# ATSAMG53 register map
Vendor: Microchip Technology; Series: SAMG53; File version: 0
CPU: CM4 r0p1, little endian, MPU, FPU, 4 interrupt priority bits
Registers are 32-bit, read-write, reset 0x0 unless marked. A register's access mark holds for its fields unless they carry their own. Offsets are from the block's base; [hi:lo] are bit positions; {n}, {i} and the like mark numbered series; 'fields as' and 'values as' point back to an identical list.

## USART — Universal Synchronous Asynchronous Receiver Transmitter
Base 0x40024000; register names take the prefix USART_
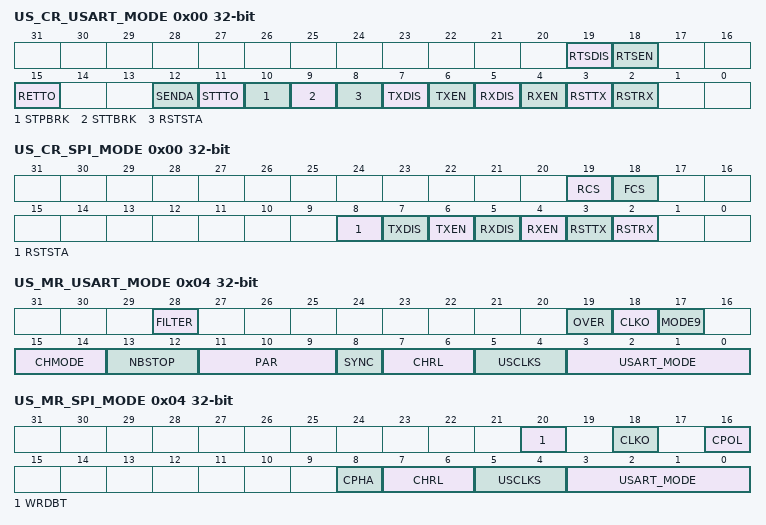
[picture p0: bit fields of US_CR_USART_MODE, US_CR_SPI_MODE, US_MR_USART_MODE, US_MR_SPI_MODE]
0x00 US_CR_USART_MODE wo — Control Register
  [19] RTSDIS — Request to Send Disable
  [18] RTSEN — Request to Send Enable
  [15] RETTO — Start Timeout Immediately
  [12] SENDA — Send Address
  [11] STTTO — Clear TIMEOUT Flag and Start Timeout After Next Character Received
  [10] STPBRK — Stop Break
  [9] STTBRK — Start Break
  [8] RSTSTA — Reset Status Bits
  [7] TXDIS — Transmitter Disable
  [6] TXEN — Transmitter Enable
  [5] RXDIS — Receiver Disable
  [4] RXEN — Receiver Enable
  [3] RSTTX — Reset Transmitter
  [2] RSTRX — Reset Receiver
0x00 US_CR_SPI_MODE wo (alternate view of US_CR_USART_MODE) — Control Register
  [19] RCS — Release SPI Chip Select
  [18] FCS — Force SPI Chip Select
  [8] RSTSTA — Reset Status Bits
  [7] TXDIS — Transmitter Disable
  [6] TXEN — Transmitter Enable
  [5] RXDIS — Receiver Disable
  [4] RXEN — Receiver Enable
  [3] RSTTX — Reset Transmitter
  [2] RSTRX — Reset Receiver
0x04 US_MR_USART_MODE — Mode Register
  [28] FILTER — Receive Line Filter
  [19] OVER — Oversampling Mode
  [18] CLKO — Clock Output Select
  [17] MODE9 — 9-bit Character Length
  [15:14] CHMODE — Channel Mode
    0=NORMAL (Normal mode); 1=AUTOMATIC (Automatic Echo. Receiver input is connected to the TXD pin.); 2=LOCAL_LOOPBACK (Local Loopback. Transmitter output is connected to the Receiver Input.); 3=REMOTE_LOOPBACK (Remote Loopback. RXD pin is internally connected to the TXD pin.)
  [13:12] NBSTOP — Number of Stop Bits
    0=_1_BIT (1 stop bit); 1=_1_5_BIT (1.5 stop bits (SYNC = 0) or reserved (SYNC = 1)); 2=_2_BIT (2 stop bits)
  [11:9] PAR — Parity Type
    0=EVEN (Even parity); 1=ODD (Odd parity); 2=SPACE (Parity forced to 0 (Space)); 3=MARK (Parity forced to 1 (Mark)); 4=NO (No parity); 6=MULTIDROP (Multidrop mode)
  [8] SYNC — Synchronous Mode Select
  [7:6] CHRL — Character Length
    {v}=_{v+5}_BIT (Character length is {v+5} bits) (v=0..3)
  [5:4] USCLKS — Clock Selection
    0=MCK (Peripheral clock is selected); 1=DIV (Peripheral clock divided (DIV=8) is selected); 3=SCK (Serial clock (SCK) is selected)
  [3:0] USART_MODE — USART Mode of Operation
    0=NORMAL (Normal mode); 1=RS485 (RS485 mode); 2=HW_HANDSHAKING (Hardware Handshaking); 14=SPI_MASTER (SPI master mode); 15=SPI_SLAVE (SPI Slave mode)
0x04 US_MR_SPI_MODE (alternate view of US_MR_USART_MODE) — Mode Register
  [20] WRDBT — Wait Read Data Before Transfer
  [18] CLKO — Clock Output Select
  [16] CPOL — SPI Clock Polarity
  [8] CPHA — SPI Clock Phase
  [7:6] CHRL — Character Length
    {v}=_{v+5}_BIT (Character length is {v+5} bits) (v=0..3)
  [5:4] USCLKS — Clock Selection
    values as US_MR_USART_MODE.USCLKS
  [3:0] USART_MODE — USART Mode of Operation
    values as US_MR_USART_MODE.USART_MODE
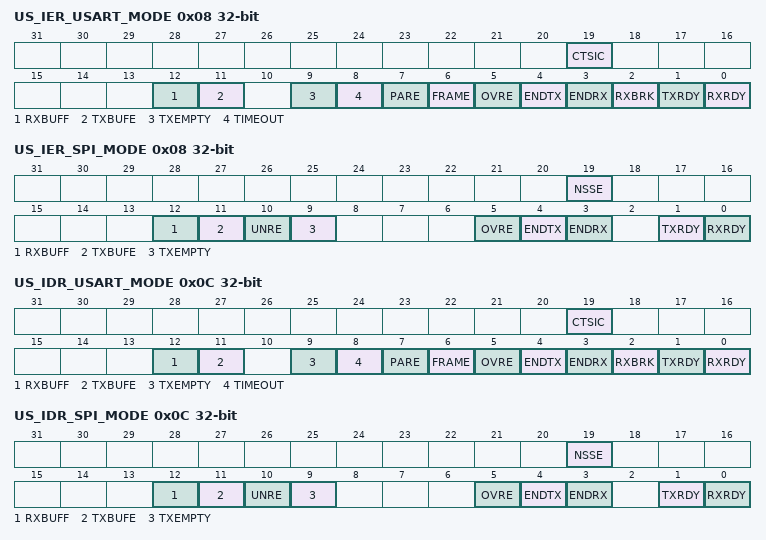
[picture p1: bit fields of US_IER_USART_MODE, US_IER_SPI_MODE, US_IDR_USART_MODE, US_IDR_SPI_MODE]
0x08 US_IER_USART_MODE wo — Interrupt Enable Register
  [19] CTSIC — Clear to Send Input Change Interrupt Enable
  [12] RXBUFF — Receive Buffer Full Interrupt Enable (available in all USART modes of operation)
  [11] TXBUFE — Transmit Buffer Empty Interrupt Enable (available in all USART modes of operation)
  [9] TXEMPTY — TXEMPTY Interrupt Enable
  [8] TIMEOUT — Time-out Interrupt Enable
  [7] PARE — Parity Error Interrupt Enable
  [6] FRAME — Framing Error Interrupt Enable
  [5] OVRE — Overrun Error Interrupt Enable
  [4] ENDTX — End of Transmit Buffer Interrupt Enable (available in all USART modes of operation)
  [3] ENDRX — End of Receive Buffer Interrupt Enable (available in all USART modes of operation)
  [2] RXBRK — Receiver Break Interrupt Enable
  [1] TXRDY — TXRDY Interrupt Enable
  [0] RXRDY — RXRDY Interrupt Enable
0x08 US_IER_SPI_MODE wo (alternate view of US_IER_USART_MODE) — Interrupt Enable Register
  [19] NSSE — NSS Line (Driving CTS Pin) Rising or Falling Edge Event Interrupt Enable
  [12] RXBUFF — Receive Buffer Full Interrupt Enable
  [11] TXBUFE — Transmit Buffer Empty Interrupt Enable
  [10] UNRE — SPI Underrun Error Interrupt Enable
  [9] TXEMPTY — TXEMPTY Interrupt Enable
  [5] OVRE — Overrun Error Interrupt Enable
  [4] ENDTX — End of Transmit Buffer Interrupt Enable
  [3] ENDRX — End of Receive Buffer Interrupt Enable
  [1] TXRDY — TXRDY Interrupt Enable
  [0] RXRDY — RXRDY Interrupt Enable
0x0C US_IDR_USART_MODE wo — Interrupt Disable Register
  fields as US_IER_USART_MODE
0x0C US_IDR_SPI_MODE wo (alternate view of US_IDR_USART_MODE) — Interrupt Disable Register
  fields as US_IER_SPI_MODE
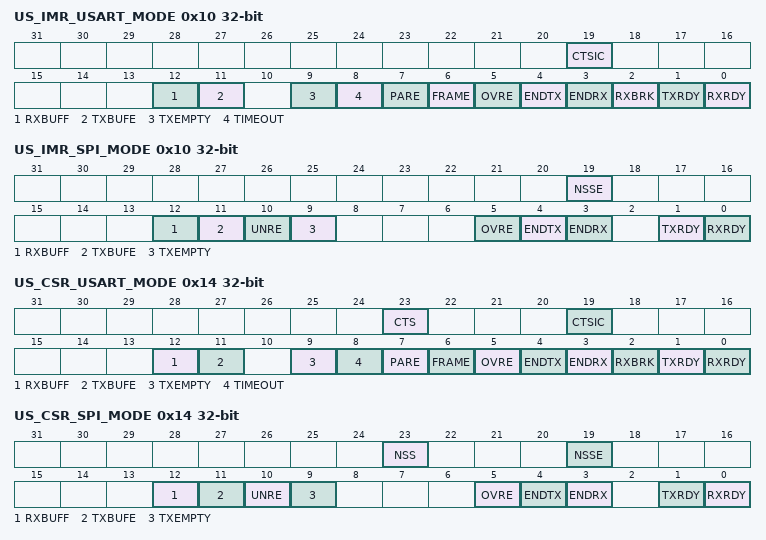
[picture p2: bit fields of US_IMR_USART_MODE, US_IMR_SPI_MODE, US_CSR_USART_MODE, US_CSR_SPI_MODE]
0x10 US_IMR_USART_MODE ro — Interrupt Mask Register
  fields as US_IER_USART_MODE
0x10 US_IMR_SPI_MODE ro (alternate view of US_IMR_USART_MODE) — Interrupt Mask Register
  fields as US_IER_SPI_MODE
0x14 US_CSR_USART_MODE ro — Channel Status Register
  [23] CTS — Image of CTS Input
  [19] CTSIC — Clear to Send Input Change Flag (cleared on read)
  [12] RXBUFF — RX Buffer Full (cleared by writing US_RCR or US_RNCR)
  [11] TXBUFE — TX Buffer Empty (cleared by writing US_TCR or US_TNCR)
  [9] TXEMPTY — Transmitter Empty (cleared by writing US_THR)
  [8] TIMEOUT — Receiver Time-out (cleared by writing a one to bit US_CR.STTTO)
  [7] PARE — Parity Error (cleared by writing a one to bit US_CR.RSTSTA)
  [6] FRAME — Framing Error (cleared by writing a one to bit US_CR.RSTSTA)
  [5] OVRE — Overrun Error (cleared by writing a one to bit US_CR.RSTSTA)
  [4] ENDTX — End of TX Buffer (cleared by writing US_TCR or US_TNCR)
  [3] ENDRX — End of RX Buffer (cleared by writing US_RCR or US_RNCR)
  [2] RXBRK — Break Received/End of Break (cleared by writing a one to bit US_CR.RSTSTA)
  [1] TXRDY — Transmitter Ready (cleared by writing US_THR)
  [0] RXRDY — Receiver Ready (cleared by reading US_RHR)
0x14 US_CSR_SPI_MODE ro (alternate view of US_CSR_USART_MODE) — Channel Status Register
  [23] NSS — Image of NSS Line
  [19] NSSE — NSS Line (Driving CTS Pin) Rising or Falling Edge Event (cleared on read)
  [12] RXBUFF — RX Buffer Full (cleared by writing US_RCR or US_RNCR)
  [11] TXBUFE — TX Buffer Empty (cleared by writing US_TCR or US_TNCR)
  [10] UNRE — Underrun Error (cleared by writing a one to bit US_CR.RSTSTA)
  [9] TXEMPTY — Transmitter Empty (cleared by writing US_THR)
  [5] OVRE — Overrun Error (cleared by writing a one to bit US_CR.RSTSTA)
  [4] ENDTX — End of TX Buffer (cleared by writing US_TCR or US_TNCR)
  [3] ENDRX — End of RX Buffer (cleared by writing US_RCR or US_RNCR)
  [1] TXRDY — Transmitter Ready (cleared by writing US_THR)
  [0] RXRDY — Receiver Ready (cleared by reading US_RHR)
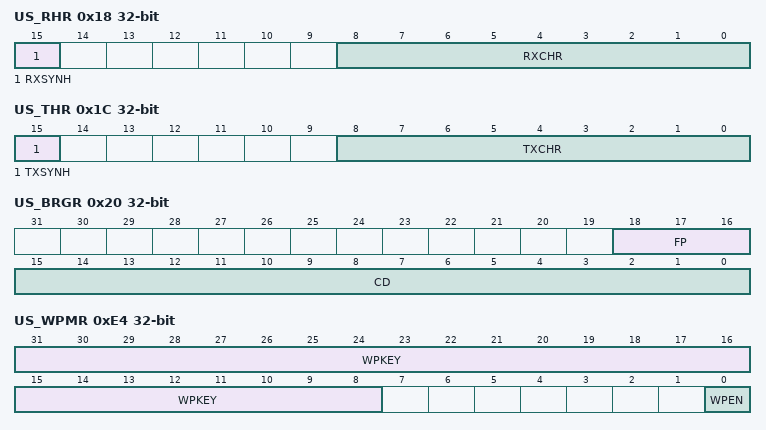
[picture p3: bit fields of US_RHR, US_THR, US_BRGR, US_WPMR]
0x18 US_RHR ro — Receive Holding Register
  [15] RXSYNH — Received Sync
  [8:0] RXCHR — Received Character
0x1C US_THR wo — Transmit Holding Register
  [15] TXSYNH — Sync Field to be Transmitted
  [8:0] TXCHR — Character to be Transmitted
0x20 US_BRGR — Baud Rate Generator Register
  [18:16] FP — Fractional Part
  [15:0] CD — Clock Divider
0x24 US_RTOR — Receiver Time-out Register
  [15:0] TO — Time-out Value
0x28 US_TTGR — Transmitter Timeguard Register
  [7:0] TG — Timeguard Value
0x44 US_NER ro — Number of Errors Register
  [7:0] NB_ERRORS — Number of Errors
0xE4 US_WPMR — Write Protection Mode Register
  [31:8] WPKEY — Write Protection Key
    0x555341=PASSWD (Writing any other value in this field aborts the write operation of the WPEN bit. Always reads as 0.)
  [0] WPEN — Write Protection Enable
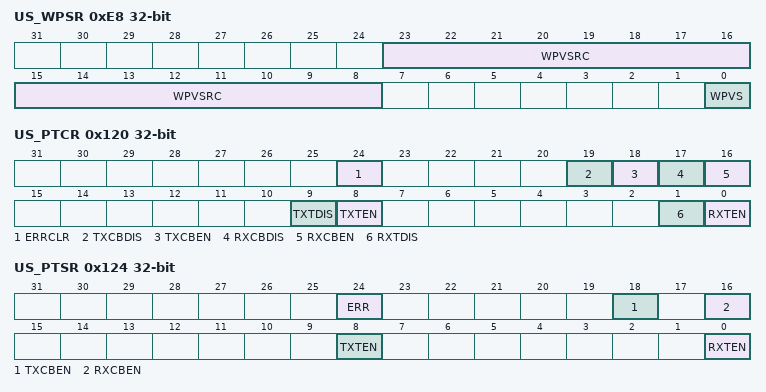
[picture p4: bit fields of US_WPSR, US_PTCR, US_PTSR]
0xE8 US_WPSR ro — Write Protection Status Register
  [23:8] WPVSRC — Write Protection Violation Source
  [0] WPVS — Write Protection Violation Status
0x100 US_RPR — Receive Pointer Register
  [31:0] RXPTR
0x104 US_RCR — Receive Counter Register
  [15:0] RXCTR
0x108 US_TPR — Transmit Pointer Register
  [31:0] TXPTR — Transmit Counter Register
0x10C US_TCR — Transmit Counter Register
  [15:0] TXCTR
0x110 US_RNPR — Receive Next Pointer Register
  [31:0] RXNPTR — Receive Next Pointer
0x114 US_RNCR — Receive Next Counter Register
  [15:0] RXNCTR — Receive Next Counter
0x118 US_TNPR — Transmit Next Pointer Register
  [31:0] TXNPTR — Transmit Next Pointer
0x11C US_TNCR — Transmit Next Counter Register
  [15:0] TXNCTR — Transmit Counter Next
0x120 US_PTCR wo — Transfer Control Register
  [24] ERRCLR — Transfer Bus Error Clear
  [19] TXCBDIS — Transmitter Circular Buffer Disable
  [18] TXCBEN — Transmitter Circular Buffer Enable
  [17] RXCBDIS — Receiver Circular Buffer Disable
  [16] RXCBEN — Receiver Circular Buffer Enable
  [9] TXTDIS — Transmitter Transfer Disable
  [8] TXTEN — Transmitter Transfer Enable
  [1] RXTDIS — Receiver Transfer Disable
  [0] RXTEN — Receiver Transfer Enable
0x124 US_PTSR ro — Transfer Status Register
  [24] ERR — Transfer Bus Error
  [18] TXCBEN — Transmitter Circular Buffer Enable
  [16] RXCBEN — Receiver Circular Buffer Enable
  [8] TXTEN — Transmitter Transfer Enable
  [0] RXTEN — Receiver Transfer Enable
